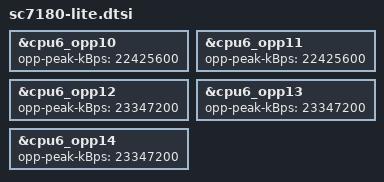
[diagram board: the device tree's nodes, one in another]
// SPDX-License-Identifier: BSD-3-Clause
/*
 * SC7180 lite device tree source
 *
 * Copyright (c) 2020, The Linux Foundation. All rights reserved.
 */

&cpu6_opp10 {
	opp-peak-kBps = <22425600>;
};

&cpu6_opp11 {
	opp-peak-kBps = <22425600>;
};

&cpu6_opp12 {
	opp-peak-kBps = <23347200>;
};

&cpu6_opp13 {
	opp-peak-kBps = <23347200>;
};

&cpu6_opp14 {
	opp-peak-kBps = <23347200>;
};
